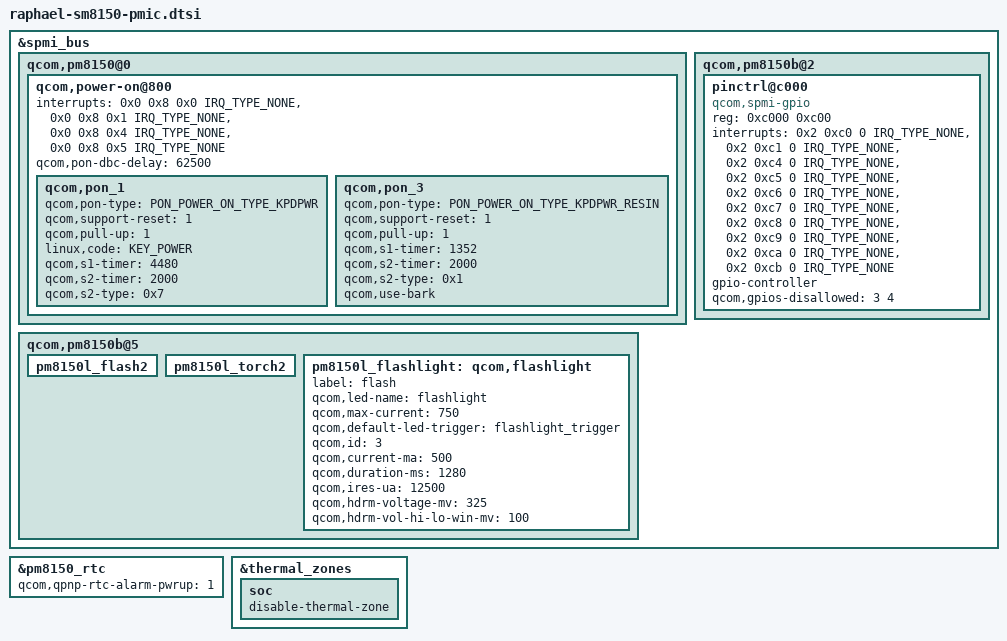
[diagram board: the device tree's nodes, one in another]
/* Copyright (c) 2020, The Linux Foundation. All rights reserved.
 *
 * This program is free software; you can redistribute it and/or modify
 * it under the terms of the GNU General Public License version 2 and
 * only version 2 as published by the Free Software Foundation.
 *
 * This program is distributed in the hope that it will be useful,
 * but WITHOUT ANY WARRANTY; without even the implied warranty of
 * MERCHANTABILITY or FITNESS FOR A PARTICULAR PURPOSE.  See the
 * GNU General Public License for more details.
 */

#include <dt-bindings/clock/qcom,rpmh.h>
#include <dt-bindings/input/input.h>
#include <dt-bindings/input/qcom,qpnp-power-on.h>
#include <dt-bindings/interrupt-controller/irq.h>
#include <dt-bindings/spmi/spmi.h>
#include <dt-bindings/iio/qcom,spmi-vadc.h>

&spmi_bus {
	#address-cells = <2>;
	#size-cells = <0>;
	qcom,pm8150@0 {
		qcom,power-on@800 {
			interrupts = <0x0 0x8 0x0 IRQ_TYPE_NONE>,
				   <0x0 0x8 0x1 IRQ_TYPE_NONE>,
				   <0x0 0x8 0x4 IRQ_TYPE_NONE>,
				   <0x0 0x8 0x5 IRQ_TYPE_NONE>;
			interrupt-names = "kpdpwr", "resin",
					"resin-bark", "kpdpwr-resin-bark";
			qcom,pon-dbc-delay = <62500>;

			qcom,pon_1 {
				qcom,pon-type = <PON_POWER_ON_TYPE_KPDPWR>;
				qcom,support-reset = <1>;
				qcom,pull-up = <1>;
				linux,code = <KEY_POWER>;
				qcom,s1-timer = <4480>;
				qcom,s2-timer = <2000>;
				qcom,s2-type = <0x7>;
			};

			qcom,pon_3 {
				qcom,pon-type = <PON_POWER_ON_TYPE_KPDPWR_RESIN>;
				qcom,support-reset = <1>;
				qcom,pull-up = <1>;
				qcom,s1-timer = <1352>;
				qcom,s2-timer = <2000>;
				qcom,s2-type = <0x1>;
				qcom,use-bark;
			};
		};
	};

	qcom,pm8150b@2 {
		pinctrl@c000 {
			compatible = "qcom,spmi-gpio";
			reg = <0xc000 0xc00>;
			interrupts = <0x2 0xc0 0 IRQ_TYPE_NONE>,
					<0x2 0xc1 0 IRQ_TYPE_NONE>,
					<0x2 0xc4 0 IRQ_TYPE_NONE>,
					<0x2 0xc5 0 IRQ_TYPE_NONE>,
					<0x2 0xc6 0 IRQ_TYPE_NONE>,
					<0x2 0xc7 0 IRQ_TYPE_NONE>,
					<0x2 0xc8 0 IRQ_TYPE_NONE>,
					<0x2 0xc9 0 IRQ_TYPE_NONE>,
					<0x2 0xca 0 IRQ_TYPE_NONE>,
					<0x2 0xcb 0 IRQ_TYPE_NONE>;
			interrupt-names = "pm8150b_gpio1", "pm8150b_gpio2",
					"pm8150b_gpio5", "pm8150b_gpio6",
					"pm8150b_gpio7", "pm8150b_gpio8",
					"pm8150b_gpio9", "pm8150b_gpio10",
					"pm8150b_gpio11", "pm8150b_gpio12";
			gpio-controller;
			#gpio-cells = <2>;
			qcom,gpios-disallowed = <3 4>;
		};
	};

        qcom,pm8150b@5 {
		pm8150l_flash2 {
			/delete-property/ status;
		};

		pm8150l_torch2 {
			/delete-property/ status;
		};

		pm8150l_flashlight: qcom,flashlight {
			label = "flash";
			qcom,led-name = "flashlight";
			qcom,max-current = <750>;
			qcom,default-led-trigger = "flashlight_trigger";
			qcom,id = <3>;
			qcom,current-ma = <500>;
			qcom,duration-ms = <1280>;
			qcom,ires-ua = <12500>;
			qcom,hdrm-voltage-mv = <325>;
			qcom,hdrm-vol-hi-lo-win-mv = <100>;
		};
	};
};

&pm8150_rtc {
	qcom,qpnp-rtc-alarm-pwrup = <1>;
};

&thermal_zones {
	soc {
		disable-thermal-zone;
	};
};

